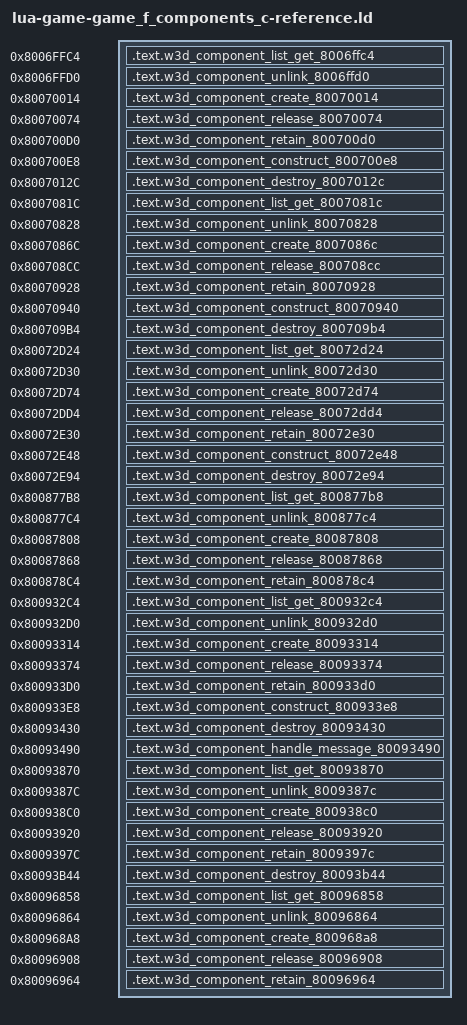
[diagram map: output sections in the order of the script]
/* Generated reference-only placements. All bodies are source-built. */
OUTPUT_FORMAT("elf32-powerpc")
OUTPUT_ARCH(powerpc)
ENTRY(w3d_component_list_get_8006ffc4)
_SDA_BASE_ = 0x804b2540;
_SDA2_BASE_ = 0x804c2540;
w3d_actor_base_destroy = 0x80161050;
w3d_actor_base_initialize = 0x80161014;
w3d_base_construct_800e7e20 = 0x800e7e20;
w3d_base_construct_800ea180 = 0x800ea180;
w3d_base_construct_8015fef0 = 0x8015fef0;
w3d_base_destroy_8002a978 = 0x8002a978;
w3d_base_destroy_800e7ed8 = 0x800e7ed8;
w3d_base_destroy_800ea324 = 0x800ea324;
w3d_base_destroy_8015ff2c = 0x8015ff2c;
w3d_base_handle_message_8015fb34 = 0x8015fb34;
w3d_component_construct_800878dc = 0x800878dc;
w3d_component_construct_80093994 = 0x80093994;
w3d_component_construct_8009697c = 0x8009697c;
w3d_component_destroy_80087a88 = 0x80087a88;
w3d_component_destroy_800969ec = 0x800969ec;
w3d_component_list_80360450 = 0x80360450;
w3d_component_list_80360480 = 0x80360480;
w3d_component_list_803604b0 = 0x803604b0;
w3d_component_list_803604e0 = 0x803604e0;
w3d_component_list_80360510 = 0x80360510;
w3d_component_list_80360540 = 0x80360540;
w3d_component_list_80360570 = 0x80360570;
w3d_component_start_8009369c = 0x8009369c;
w3d_component_stop_80093780 = 0x80093780;
w3d_component_vtable_8040f000 = 0x8040f000;
w3d_component_vtable_8040f048 = 0x8040f048;
w3d_component_vtable_8040f0e0 = 0x8040f0e0;
w3d_component_vtable_8040f1b8 = 0x8040f1b8;
w3d_component_vtable_8040f1f8 = 0x8040f1f8;
w3d_heap_allocate_entry_a = 0x801fe1d8;
w3d_owner_list_remove = 0x8020fd2c;
w3d_state_register = 0x8020fd04;
SECTIONS {
  .text.w3d_component_list_get_8006ffc4 0x8006ffc4 : { *(.text.w3d_component_list_get_8006ffc4) }
  .text.w3d_component_unlink_8006ffd0 0x8006ffd0 : { *(.text.w3d_component_unlink_8006ffd0) }
  .text.w3d_component_create_80070014 0x80070014 : { *(.text.w3d_component_create_80070014) }
  .text.w3d_component_release_80070074 0x80070074 : { *(.text.w3d_component_release_80070074) }
  .text.w3d_component_retain_800700d0 0x800700d0 : { *(.text.w3d_component_retain_800700d0) }
  .text.w3d_component_construct_800700e8 0x800700e8 : { *(.text.w3d_component_construct_800700e8) }
  .text.w3d_component_destroy_8007012c 0x8007012c : { *(.text.w3d_component_destroy_8007012c) }
  .text.w3d_component_list_get_8007081c 0x8007081c : { *(.text.w3d_component_list_get_8007081c) }
  .text.w3d_component_unlink_80070828 0x80070828 : { *(.text.w3d_component_unlink_80070828) }
  .text.w3d_component_create_8007086c 0x8007086c : { *(.text.w3d_component_create_8007086c) }
  .text.w3d_component_release_800708cc 0x800708cc : { *(.text.w3d_component_release_800708cc) }
  .text.w3d_component_retain_80070928 0x80070928 : { *(.text.w3d_component_retain_80070928) }
  .text.w3d_component_construct_80070940 0x80070940 : { *(.text.w3d_component_construct_80070940) }
  .text.w3d_component_destroy_800709b4 0x800709b4 : { *(.text.w3d_component_destroy_800709b4) }
  .text.w3d_component_list_get_80072d24 0x80072d24 : { *(.text.w3d_component_list_get_80072d24) }
  .text.w3d_component_unlink_80072d30 0x80072d30 : { *(.text.w3d_component_unlink_80072d30) }
  .text.w3d_component_create_80072d74 0x80072d74 : { *(.text.w3d_component_create_80072d74) }
  .text.w3d_component_release_80072dd4 0x80072dd4 : { *(.text.w3d_component_release_80072dd4) }
  .text.w3d_component_retain_80072e30 0x80072e30 : { *(.text.w3d_component_retain_80072e30) }
  .text.w3d_component_construct_80072e48 0x80072e48 : { *(.text.w3d_component_construct_80072e48) }
  .text.w3d_component_destroy_80072e94 0x80072e94 : { *(.text.w3d_component_destroy_80072e94) }
  .text.w3d_component_list_get_800877b8 0x800877b8 : { *(.text.w3d_component_list_get_800877b8) }
  .text.w3d_component_unlink_800877c4 0x800877c4 : { *(.text.w3d_component_unlink_800877c4) }
  .text.w3d_component_create_80087808 0x80087808 : { *(.text.w3d_component_create_80087808) }
  .text.w3d_component_release_80087868 0x80087868 : { *(.text.w3d_component_release_80087868) }
  .text.w3d_component_retain_800878c4 0x800878c4 : { *(.text.w3d_component_retain_800878c4) }
  .text.w3d_component_list_get_800932c4 0x800932c4 : { *(.text.w3d_component_list_get_800932c4) }
  .text.w3d_component_unlink_800932d0 0x800932d0 : { *(.text.w3d_component_unlink_800932d0) }
  .text.w3d_component_create_80093314 0x80093314 : { *(.text.w3d_component_create_80093314) }
  .text.w3d_component_release_80093374 0x80093374 : { *(.text.w3d_component_release_80093374) }
  .text.w3d_component_retain_800933d0 0x800933d0 : { *(.text.w3d_component_retain_800933d0) }
  .text.w3d_component_construct_800933e8 0x800933e8 : { *(.text.w3d_component_construct_800933e8) }
  .text.w3d_component_destroy_80093430 0x80093430 : { *(.text.w3d_component_destroy_80093430) }
  .text.w3d_component_handle_message_80093490 0x80093490 : { *(.text.w3d_component_handle_message_80093490) }
  .text.w3d_component_list_get_80093870 0x80093870 : { *(.text.w3d_component_list_get_80093870) }
  .text.w3d_component_unlink_8009387c 0x8009387c : { *(.text.w3d_component_unlink_8009387c) }
  .text.w3d_component_create_800938c0 0x800938c0 : { *(.text.w3d_component_create_800938c0) }
  .text.w3d_component_release_80093920 0x80093920 : { *(.text.w3d_component_release_80093920) }
  .text.w3d_component_retain_8009397c 0x8009397c : { *(.text.w3d_component_retain_8009397c) }
  .text.w3d_component_destroy_80093b44 0x80093b44 : { *(.text.w3d_component_destroy_80093b44) }
  .text.w3d_component_list_get_80096858 0x80096858 : { *(.text.w3d_component_list_get_80096858) }
  .text.w3d_component_unlink_80096864 0x80096864 : { *(.text.w3d_component_unlink_80096864) }
  .text.w3d_component_create_800968a8 0x800968a8 : { *(.text.w3d_component_create_800968a8) }
  .text.w3d_component_release_80096908 0x80096908 : { *(.text.w3d_component_release_80096908) }
  .text.w3d_component_retain_80096964 0x80096964 : { *(.text.w3d_component_retain_80096964) }
  /DISCARD/ : { *(.text*) *(.rodata*) *(.data*) *(.bss*) *(.sdata*) *(.sbss*) *(.comment) }
}
